# SG2000 register map
Vendor: Sophgo
Registers are 32-bit, read-write, reset 0x0 unless marked. A register's access mark holds for its fields unless they carry their own. Offsets are from the block's base; lines under a group give offsets from that group; [hi:lo] are bit positions; {n}, {i} and the like mark numbered series; 'fields as' and 'values as' point back to an identical list; <NAME> marks a mode.

## Memory map
0x01900000 mailboxes
0x03020000 GPIO0 size 0x64
0x03021000 GPIO1 size 0x64
0x03022000 GPIO2 size 0x64
0x03023000 GPIO3 size 0x64
0x04140000 UART0 size 0xAC — UART
0x04150000 UART1 size 0xAC
0x04160000 UART2 size 0xAC
0x04170000 UART3 size 0xAC
0x041C0000 UART4 size 0xAC
0x05021000 RTCSYS_GPIO size 0x64
0x05022000 RTCSYS_UART size 0xAC
0x70000000 plic size 0x4000000 — Platform-Level Interrupt Controller
0x74004000 mtimecmp size 0x8 — Timer Interrupt Value

## Interrupts
30 UART0
31 UART1
41 GPIO0
42 GPIO1
43 GPIO2
44 GPIO3
61 MBOX (mailboxes)

## plic — Platform-Level Interrupt Controller
Base 0x70000000
{0x0+4i} priority[{i}] (i=0..1023) — Interrupt priority
{0x2000+0x80*i} enable[{i}] (i=0..15871) group — Interrupt Enable Registers
  {0x0+4j} bits[{j}] (j=0..31) access not given — Interrupt Enable Bits
{0x200000+0x1000*i} priority_threshold[{i}] (i=0..15871) — Interrupt Priority Threshold
{0x200004+0x1000*i} claim[{i}] (i=0..15871) — Interrupt Claim/Completion

## mtimecmp — Timer Interrupt Value
Base 0x74004000
0x00 mtimecmp_low — Low Bits Of Mtimecmp
0x04 mtimecmp_high — Low Bits Of Mtimecmp

## GPIO0
Base 0x03020000
Same registers: GPIO1 0x03021000, GPIO2 0x03022000, GPIO3 0x03023000, RTCSYS_GPIO 0x05021000
0x00 DR — Data Register
0x04 DDR — Data Direction Register
0x30 INTEN — Interrupt Enable Register
0x34 INTMASK — Interrupt Mask Register
0x38 INTTYPE_LEVEL — Interrupt Level Register
0x3C INT_POLARITY — Interrupt Polarity Register
0x40 INTSTATUS ro reset not defined — Interrupt Status Register
0x44 RAW_INTSTATUS ro reset not defined — Raw (pre-masking) Interrupt Status Register
0x48 DEBOUNCE — Debounce Enable Register
0x4C EOI — Clear Interrupt Register
0x50 EXT ro reset not defined — External Port Register
0x60 LS_SYNC — Level-Sensitive Synchronization Enable Register
  [0] LS_SYNC — Synchronize all level-sensitive interrupt to pclk_intr

## UART0 — UART
Base 0x04140000
Same registers: UART1 0x04150000, UART2 0x04160000, UART3 0x04170000, UART4 0x041C0000, RTCSYS_UART 0x05022000
0x00 RBR_THR_DLL — Receive Buffer,Transmit Holding or Divisor Latch Low byte Register
  [7:0] RBR_THR_DLL
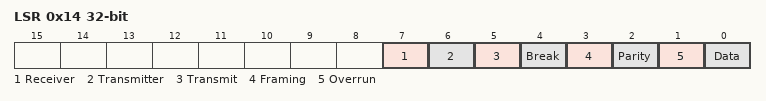
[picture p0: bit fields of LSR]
0x14 LSR ro reset not defined — Line Status Register
  [7] Receiver FIFO Error Bit, [6] Transmitter Empty Bit, [5] Transmit Holding Register Empty Bit, [4] Break Interrupt Bit, [3] Framing Error Bit, [2] Parity Error Bit, [1] Overrun Error Bit, [0] Data Ready Bit

## mailboxes
Base 0x01900000
{0x0+4i} cpu_mbox_en[{i}] (i=0..3) 8-bit — Mailbox Enable Bits
{0x10+0x10*i} cpu_mbox_set[{i}] (i=0..3) group — Interrupts Registers
  0x00 int_clr 8-bit — Interrupt Clear
  0x04 int_mask 8-bit — Interrupt Mask
  0x08 int_int 8-bit — Interrupt Status
  0x0C int_raw 8-bit — Interrupt Raw
0x60 mbox_set 8-bit
0x64 mbox_status 8-bit
{0x70+4i} cpu_mbox_status[{i}] (i=0..3) 8-bit
{0xC0+4i} spinlock[{i}] (i=0..7)
{0x400+4i} context[{i}] (i=0..15) — Data For The Messages
